VERSION ""

NS_ :

BS_:

BU_: DAQ_PICO DASH

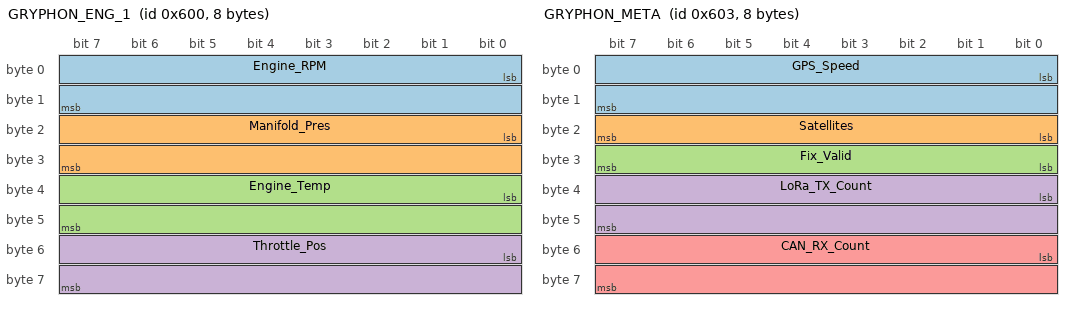
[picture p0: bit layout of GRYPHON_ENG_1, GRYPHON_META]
BO_ 1536 GRYPHON_ENG_1: 8 DAQ_PICO
 SG_ Engine_RPM : 0|16@1+ (1,0) [0|15000] "RPM" DASH
 SG_ Manifold_Pres : 16|16@1+ (0.1,0) [0|300] "kPa" DASH
 SG_ Engine_Temp : 32|16@1- (0.1,0) [-20|150] "C" DASH
 SG_ Throttle_Pos : 48|16@1+ (0.1,0) [0|100] "%" DASH

BO_ 1537 GRYPHON_ENG_2: 8 DAQ_PICO
 SG_ Battery_Voltage : 0|16@1+ (0.01,0) [0|20] "V" DASH
 SG_ Air_Temp : 16|16@1- (0.1,0) [-20|150] "C" DASH

BO_ 1538 GRYPHON_GPS_POS: 8 DAQ_PICO
 SG_ Latitude : 0|32@1- (0.0000001,0) [-90|90] "deg" DASH
 SG_ Longitude : 32|32@1- (0.0000001,0) [-180|180] "deg" DASH

BO_ 1539 GRYPHON_META: 8 DAQ_PICO
 SG_ GPS_Speed : 0|16@1+ (0.1,0) [0|300] "kph" DASH
 SG_ Satellites : 16|8@1+ (1,0) [0|50] "" DASH
 SG_ Fix_Valid : 24|8@1+ (1,0) [0|1] "bool" DASH
 SG_ LoRa_TX_Count : 32|16@1+ (1,0) [0|65535] "count" DASH
 SG_ CAN_RX_Count : 48|16@1+ (1,0) [0|65535] "count" DASH

BA_DEF_ "BusType" STRING ;
BA_DEF_DEF_ "BusType" "CAN";
